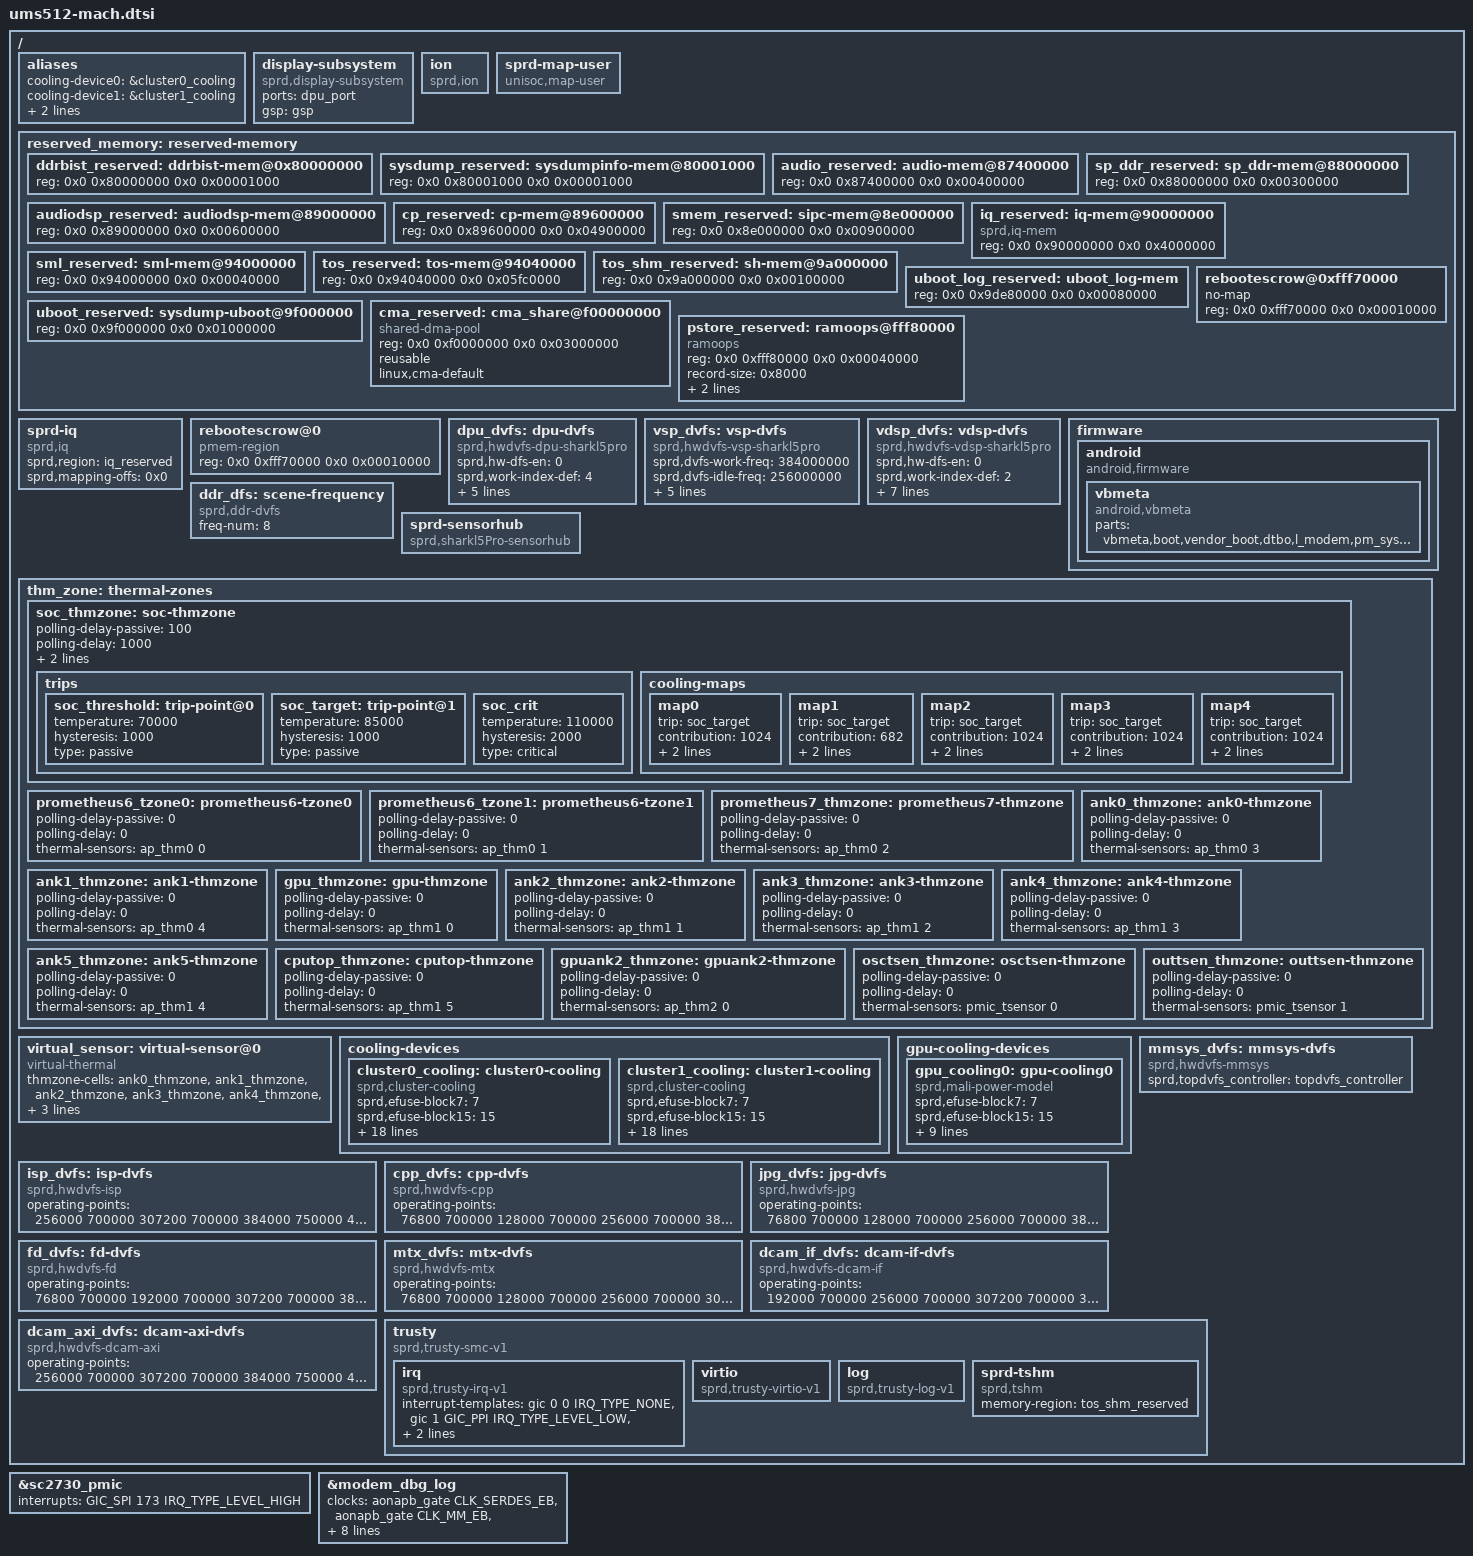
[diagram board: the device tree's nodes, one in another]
/*
 * Spreadtrum Sharkl5Pro board common DTS file
 *
 * Copyright (C) 2018, Spreadtrum Communications Inc.
 *
 * This file is licensed under a dual GPLv2 or X11 license.
 */

#include <dt-bindings/thermal/thermal.h>

/ {
	aliases {
		cooling-device0 = &cluster0_cooling;
		cooling-device1 = &cluster1_cooling;
		gpu-cooling0 = &gpu_cooling0;
		thm-sensor0 = &virtual_sensor;
	};

	display-subsystem {
		compatible = "sprd,display-subsystem";
		ports = <&dpu_port>;
		gsp = <&gsp>;
	};

	ion: ion {
		compatible = "sprd,ion";
		#address-cells = <1>;
		#size-cells = <0>;
	};

	sprd-map-user {
		compatible = "unisoc,map-user";
	};

	reserved_memory: reserved-memory {
		#address-cells = <2>;
		#size-cells = <2>;
		ranges;

		ddrbist_reserved: ddrbist-mem@0x80000000 {
			reg = <0x0 0x80000000 0x0 0x00001000>;
		};

		sysdump_reserved: sysdumpinfo-mem@80001000 {
			reg = <0x0 0x80001000 0x0 0x00001000>;
		};

		audio_reserved: audio-mem@87400000 {
			reg = <0x0 0x87400000 0x0 0x00400000>;
		};

		sp_ddr_reserved: sp_ddr-mem@88000000 {
			reg = <0x0 0x88000000 0x0 0x00300000>;
		};

		audiodsp_reserved: audiodsp-mem@89000000 {
			reg = <0x0 0x89000000 0x0 0x00600000>;
		};

		cp_reserved: cp-mem@89600000 {
			reg = <0x0 0x89600000 0x0 0x04900000>;
		};

		smem_reserved: sipc-mem@8e000000 {
			reg = <0x0 0x8e000000 0x0 0x00900000>;
		};

		/* Only used for iq, will be removed in normal mode by uboot */
		iq_reserved: iq-mem@90000000{
			compatible = "sprd,iq-mem";
			reg = <0x0 0x90000000 0x0 0x4000000>;
		};

		sml_reserved: sml-mem@94000000 {
			reg = <0x0 0x94000000 0x0 0x00040000>;
		};

		tos_reserved: tos-mem@94040000 {
			reg = <0x0 0x94040000 0x0 0x05fc0000>;
		};

		tos_shm_reserved: sh-mem@9a000000{
			reg = <0x0 0x9a000000 0x0 0x00100000>;
		};

		/* The uboot_log_reserved node is added in uboot. base:0x9de8 0000, size:0x80000 */
		uboot_log_reserved: uboot_log-mem {
			reg = <0x0 0x9de80000 0x0 0x00080000>;
		};

		/* Only for userdebug, will be removed in user mode by uboot */
		uboot_reserved: sysdump-uboot@9f000000 {
			reg = <0x0 0x9f000000 0x0 0x01000000>;
		};

		cma_reserved: cma_share@f00000000 {
			compatible = "shared-dma-pool";
			reg = <0x0 0xf0000000 0x0 0x03000000>;
			reusable;
			linux,cma-default;
		};

		rebootescrow@0xfff70000 {
			no-map;
			reg = <0x0 0xfff70000 0x0 0x00010000>; /* 64K */
		};

		pstore_reserved: ramoops@fff80000 {
			compatible = "ramoops";
			reg = <0x0 0xfff80000 0x0 0x00040000>;
			record-size = <0x8000>;
			console-size = <0x8000>;
			pmsg-size = <0x8000>;
		};
	};

	sprd-iq {
		compatible = "sprd,iq";
		sprd,region = <&iq_reserved>;
		sprd,mapping-offs = <0x0>;
	};

	rebootescrow@0 {
		compatible = "pmem-region";
		reg = <0x0 0xfff70000 0x0 0x00010000>;
	};

	dpu_dvfs: dpu-dvfs {
		compatible = "sprd,hwdvfs-dpu-sharkl5pro";
		sprd,hw-dfs-en = <0>;
		sprd,work-index-def = <4>;
		sprd,idle-index-def = <1>;
		sprd,freq-upd-delay-en = <0>;
		sprd,freq-upd-hdsk-en = <1>;

		operating-points = <
			/* kHz    uV */
			153600    700000
			192000    700000
			256000    700000
			307200    700000
			384000    750000
			>;
	};

	vsp_dvfs: vsp-dvfs {
		compatible = "sprd,hwdvfs-vsp-sharkl5pro";
		sprd,dvfs-work-freq = <384000000>;
		sprd,dvfs-idle-freq = <256000000>;
		sprd,dvfs-enable-flag = <1>;
		sprd,freq-upd-delay-en = <0>;
		sprd,freq-upd-hdsk-en = <1>;

		operating-points = <
			/* kHz    uV */
			256000    700000
			307200    700000
			384000    750000
			>;
	};

	vdsp_dvfs: vdsp-dvfs {
		compatible = "sprd,hwdvfs-vdsp-sharkl5pro";
		sprd,hw-dfs-en = <0>;
		sprd,work-index-def = <2>;
		sprd,idle-index-def = <1>;
		sprd,freq-upd-delay-en = <0>;
		sprd,freq-upd-hdsk-en = <1>;
		operating-points = <
			/* kHz    uV */
			256000    700000
			384000    700000
			512000    700000
			614400    750000
			768000    750000
			936000    800000
		>;
		clock-names = "vdsp_twpll",
				"vdsp_lpll",
				"vdsp_isppll";
		clocks = <&pll2 CLK_TWPLL>,
			<&pll2 CLK_LPLL>,
			<&pll2 CLK_ISPPLL>;
	};

	firmware {
		android {
			compatible = "android,firmware";
			vbmeta {
				compatible = "android,vbmeta";
				parts = "vbmeta,boot,vendor_boot,dtbo,l_modem,pm_sys,l_ldsp,l_gdsp,l_agdsp,l_cdsp";
			};
		};
	};

	ddr_dfs: scene-frequency {
		compatible = "sprd,ddr-dvfs";
		freq-num = <8>;
	};

	sprd-sensorhub {
		 compatible = "sprd,sharkl5Pro-sensorhub", "sprd,sensor-hub";
	};

	thm_zone: thermal-zones {
		soc_thmzone: soc-thmzone {
			polling-delay-passive = <100>;
			polling-delay = <1000>;
			sustainable-power = <5800>;
			thermal-sensors = <&virtual_sensor  0>;
			trips {
				soc_threshold: trip-point@0 {
					temperature = <70000>;
					hysteresis = <1000>;
					type = "passive";
				};
				soc_target: trip-point@1 {
					temperature = <85000>;
					hysteresis = <1000>;
					type = "passive";
				};
				soc_crit: soc_crit {
					temperature = <110000>;
					hysteresis = <2000>;
					type = "critical";
				};
			};
			cooling-maps {
				map0 {
					trip = <&soc_target>;
					contribution = <1024>;
					cooling-device =
					<&CPU0 THERMAL_NO_LIMIT \
					THERMAL_NO_LIMIT>;
				};
				map1 {
					trip = <&soc_target>;
					contribution = <682>;
					cooling-device =
					<&CPU6 THERMAL_NO_LIMIT \
					THERMAL_NO_LIMIT>;
				};
				map2 {
					trip = <&soc_target>;
					contribution = <1024>;
					cooling-device =
					<&cluster0_cooling THERMAL_NO_LIMIT \
					THERMAL_NO_LIMIT>;
				};
				map3 {
					trip = <&soc_target>;
					contribution = <1024>;
					cooling-device =
					<&cluster1_cooling THERMAL_NO_LIMIT \
					THERMAL_NO_LIMIT>;
				};
				map4 {
					trip = <&soc_target>;
					contribution = <1024>;
					cooling-device =
					<&gpu_cooling0 THERMAL_NO_LIMIT \
					THERMAL_NO_LIMIT>;
				};
			};
		};

		prometheus6_tzone0: prometheus6-tzone0 {
			polling-delay-passive = <0>;
			polling-delay = <0>;
			thermal-sensors = <&ap_thm0 0>;
		};

		prometheus6_tzone1: prometheus6-tzone1 {
			polling-delay-passive = <0>;
			polling-delay = <0>;
			thermal-sensors = <&ap_thm0 1>;
		};

		prometheus7_thmzone: prometheus7-thmzone {
			polling-delay-passive = <0>;
			polling-delay = <0>;
			thermal-sensors = <&ap_thm0 2>;
		};

		ank0_thmzone: ank0-thmzone {
			polling-delay-passive = <0>;
			polling-delay = <0>;
			thermal-sensors = <&ap_thm0 3>;
		};

		ank1_thmzone: ank1-thmzone {
			polling-delay-passive = <0>;
			polling-delay = <0>;
			thermal-sensors = <&ap_thm0 4>;
		};

		gpu_thmzone: gpu-thmzone {
			polling-delay-passive = <0>;
			polling-delay = <0>;
			thermal-sensors = <&ap_thm1 0>;
		};

		ank2_thmzone: ank2-thmzone {
			polling-delay-passive = <0>;
			polling-delay = <0>;
			thermal-sensors = <&ap_thm1 1>;
		};

		ank3_thmzone: ank3-thmzone {
			polling-delay-passive = <0>;
			polling-delay = <0>;
			thermal-sensors = <&ap_thm1 2>;
		};

		ank4_thmzone: ank4-thmzone {
			polling-delay-passive = <0>;
			polling-delay = <0>;
			thermal-sensors = <&ap_thm1 3>;
		};

		ank5_thmzone: ank5-thmzone {
			polling-delay-passive = <0>;
			polling-delay = <0>;
			thermal-sensors = <&ap_thm1 4>;
		};

		cputop_thmzone: cputop-thmzone {
			polling-delay-passive = <0>;
			polling-delay = <0>;
			thermal-sensors = <&ap_thm1 5>;
		};

		gpuank2_thmzone: gpuank2-thmzone {
			polling-delay-passive = <0>;
			polling-delay = <0>;
			thermal-sensors = <&ap_thm2 0>;
		};

		osctsen_thmzone: osctsen-thmzone {
			polling-delay-passive = <0>;
			polling-delay = <0>;
			thermal-sensors = <&pmic_tsensor 0>;
		};

		outtsen_thmzone: outtsen-thmzone {
			polling-delay-passive = <0>;
			polling-delay = <0>;
			thermal-sensors = <&pmic_tsensor 1>;
		};
	};

	virtual_sensor: virtual-sensor@0 {
			compatible = "virtual-thermal";
			#thermal-sensor-cells = <1>;
			thmzone-cells = <&ank0_thmzone>, <&ank1_thmzone>, <&ank2_thmzone>,
				<&ank3_thmzone>, <&ank4_thmzone>, <&ank5_thmzone>,
				<&prometheus6_tzone0>, <&prometheus6_tzone1>,
				<&prometheus7_thmzone>, <&gpu_thmzone>;
	};

	cooling-devices {
		cluster0_cooling: cluster0-cooling {
			compatible = "sprd,cluster-cooling";
			#cooling-cells = <2>; /* min followed by max */
			sprd,efuse-block7 = <7>;
			sprd,efuse-block15 = <15>;
			/* core_leak =                             */
			/*(LIT_LEAK[4:0]+1) x 2mA x 0.85V x 18.69% */
			sprd,leak-core = <2 85 1869>;
			/* cluster_leak =                           */
			/* (LIT_LEAK[4:0]+1) x 2mA x 0.85V x 25.24% */
			sprd,leak-cluster = <2 85 2524>;
			/*core Tscale = aT^3 + bT^2 + cT +di   */
			sprd,core-temp-scale =
			/* a*10^7   b*10^7      c*10^7     d*10^7 */
			<  18      (-1280)      96270    (-126100)>;
			/*core Vscale = eV^3 + fV^2 + gV + h */
			sprd,core-voltage-scale =
			/* e*10^2   f*10^2     g*10^2  h*10^2*/
			<  480     (-949)      738      (-170)>;
			/*cluster Tscale = aT^3 + bT^2 + cT +di   */
			sprd,cluster-temp-scale =
			/* a*10^7   b*10^7      c*10^7     d*10^7 */
			<  22      (-1822)      120376    (-427426)>;
			/*cluster Vscale = eV^3 + fV^2 + gV + h */
			sprd,cluster-voltage-scale =
			/* e*10^2   f*10^2     g*10^2  h*10^2*/
			<  787     (-1623)      1231      (-295)>;
			sprd,efuse-switch = <0>;
			sprd,hotplug-period = <10>;
			sprd,min-cpufreq = <614400>;
			sprd,min-cpunum = <6>;
			sprd,max-temp = <90000>;
			sprd,core-base = <3950>;
			sprd,cluster-base = <3896>;
			sprd,dynamic-core =
			/*Pdynperghz*10    Freq     Vbase  */
			< 927           1000     1000>;
			sprd,dynamic-cluster =
			/*Pdynperghz*10    Freq     Vbase  */
			< 246           1000     1000>;
		};

		cluster1_cooling: cluster1-cooling {
			compatible = "sprd,cluster-cooling";
			#cooling-cells = <2>; /* min followed by max */
			sprd,efuse-block7 = <7>;
			sprd,efuse-block15 = <15>;
			/* core_leak =                             */
			/*(LIT_LEAK[4:0]+1) x 2mA x 0.85V x 18.69% */
			sprd,leak-core = <8 85 1984>;
			/* cluster_leak =                           */
			/* (LIT_LEAK[4:0]+1) x 2mA x 0.85V x 25.24% */
			sprd,leak-cluster = <8 85 2064>;
			/*core Tscale = aT^3 + bT^2 + cT +d  */
			sprd,core-temp-scale =
			/* a*10^7   b*10^7	c*10^7	   d*10^7*/
			<  18      (-1253)      93272    (-163827)>;
			/* core  Vscale = eV^3 + fV^2 + gV + h */
			sprd,core-voltage-scale =
			/* e*10^2  f*10^2     g*10^2  h*10^2*/
			<  364     (-708)      571      (-128)>;
			/*cluster Tscale = aT^3 + bT^2 + cT +di   */
			sprd,cluster-temp-scale =
			/* a*10^7   b*10^7      c*10^7     d*10^7 */
			<  22      (-1822)      120376    (-427426)>;
			/*cluster Vscale = eV^3 + fV^2 + gV + h */
			sprd,cluster-voltage-scale =
			/* e*10^2   f*10^2     g*10^2  h*10^2*/
			<  787     (-1623)      1231      (-295)>;
			sprd,efuse-switch = <0>;
			sprd,hotplug-period = <10>;
			sprd,min-cpufreq = <1228800>;
			sprd,min-cpunum = <0>;
			sprd,max-temp = <85000>;
			sprd,core-base = <11552>;
			sprd,cluster-base = <3896>;
			sprd,dynamic-core =
			/* Pdynperghz*10    Freq     Vbase */
			<  4556          1000     1000>;
			sprd,dynamic-cluster =
			/* Pdynperghz*10    Freq     Vbase */
			<  246            1000     1000>;
		};
	};

	gpu-cooling-devices {
		gpu_cooling0: gpu-cooling0 {
			compatible = "sprd,mali-power-model";
			#cooling-cells = <2>;
			sprd,efuse-block7 = <7>;
			sprd,efuse-block15 = <15>;
			/* core_leak =                             */
			/*(LIT_LEAK[4:0]+1) x 2mA x 0.85V x 18.69% */
			sprd,leak-core = <2 85 1869>;
			/* cluster_leak =                           */
			/* (LIT_LEAK[4:0]+1) x 2mA x 0.85V x 25.24% */
			sprd,leak-cluster = <2 85 2524>;
			/*Tscale = aT^3 + bT^2 + cT +di   */
			sprd,temp-scale =
			/* a*10^7   b*10^7      c*10^7     d*10^7 */
			<  25     (-2204)     131423    (-740872)>;
			/*Vscale = eV^3 + fV^2 + gV + h */
			sprd,voltage-scale =
			/* e*10^2   f*10^2     g*10^2      h*10^2*/
			<  801  (-1712)       1335     (-324)>;
			sprd,hotplug-period = <0>;
			/* core Vbase*10^2*/
			sprd,core-base = <9343>;
			/* cluster Vbase*10^2*/
			sprd,cluster-base = <966>;
			sprd,dynamic-core =
			/*Pdynperghz*10^2    Freq     Vbase  */
			< 7150           850     800>;
			sprd,dynamic-cluster =
			/*Pdynperghz*10^2    Freq     Vbase  */
			< 6064           768     900>;
		};
	};

	isp_dvfs: isp-dvfs {
		compatible = "sprd,hwdvfs-isp";
		operating-points = <
			/* kHz    uV */
			256000    700000
			307200    700000
			384000    750000
			468000    750000
			512000    750000
			>;
	};

	cpp_dvfs: cpp-dvfs {
		compatible = "sprd,hwdvfs-cpp";
		operating-points = <
			/* kHz    uV */
			76800     700000
			128000    700000
			256000    700000
			384000    750000
			>;
	};

	jpg_dvfs: jpg-dvfs {
		compatible = "sprd,hwdvfs-jpg";
		operating-points = <
			/* kHz    uV */
			76800     700000
			128000    700000
			256000    700000
			384000    750000
			>;
	};

	fd_dvfs: fd-dvfs {
		compatible = "sprd,hwdvfs-fd";
		operating-points = <
			/* kHz    uV */
			76800     700000
			192000    700000
			307200    700000
			384000    750000
			>;
	};

	mtx_dvfs: mtx-dvfs {
		compatible = "sprd,hwdvfs-mtx";
		operating-points = <
			/* kHz    uV */
			76800     700000
			128000    700000
			256000    700000
			307200    700000
			384000    750000
			468000    750000
			512000    800000
			>;
	};

	dcam_if_dvfs: dcam-if-dvfs {
		compatible = "sprd,hwdvfs-dcam-if";
		operating-points = <
			/* kHz    uV */
			192000    700000
			256000    700000
			307200    700000
			384000    750000
			468000    750000
			>;
	};

	dcam_axi_dvfs: dcam-axi-dvfs {
		compatible = "sprd,hwdvfs-dcam-axi";
		operating-points = <
			/* kHz    uV */
			256000    700000
			307200    700000
			384000    750000
			468000    750000
			>;
	};

	mmsys_dvfs: mmsys-dvfs {
		compatible = "sprd,hwdvfs-mmsys";
		sprd,topdvfs_controller = <&topdvfs_controller>;
	};

	trusty {
		compatible = "sprd,trusty-smc-v1";

		irq {
			compatible = "sprd,trusty-irq-v1";
			interrupt-templates = <&gic 0 0 IRQ_TYPE_NONE>,
					      <&gic 1 GIC_PPI IRQ_TYPE_LEVEL_LOW>,
					      <&gic 1 GIC_SPI IRQ_TYPE_LEVEL_HIGH>;
			interrupt-ranges = < 0  15 0>,
					   <16  31 1>,
					   <32 223 2>;
		};

		virtio {
			compatible = "sprd,trusty-virtio-v1";
		};

		log {
			compatible = "sprd,trusty-log-v1";
		};

		sprd-tshm {
			compatible = "sprd,tshm";
			memory-region = <&tos_shm_reserved>;
		};
	};
};

&sc2730_pmic {
	interrupts = <GIC_SPI 173 IRQ_TYPE_LEVEL_HIGH>;
};

&modem_dbg_log{
	status = "okay";
	clock-names = "serdes_eb", "mm_eb", "ana_eb", "dphy_cfg_eb", "dphy_ref_eb", "dsi_csi_test_eb", "cphy_cfg_eb";
	clocks = <&aonapb_gate CLK_SERDES_EB>, <&aonapb_gate CLK_MM_EB>, <&aonapb_gate CLK_ANA_EB>, <&aonapb_gate CLK_SDPHY_CFG_EB>,
		<&aonapb_gate CLK_SDPHY_REF_EB>, <&aonapb_gate CLK_DSI_CSI_TEST_EB>, <&aonapb_gate CLK_CPHY_CFG_EN>;
	vddio-supply = <&vddcamio>;
	mipi-switch-en-gpios = <&ap_gpio 55 GPIO_ACTIVE_HIGH>;
	mipi-switch-mode-gpios = <&ap_gpio 8 GPIO_ACTIVE_HIGH>;
};

